# STM32N657 register map
File version: 1.0
CPU: CM55 r0p1, little endian, no MPU, FPU, vendor SysTick, 8 interrupt priority bits
Registers are 32-bit, read-write, reset 0x0 unless marked. A register's access mark holds for its fields unless they carry their own. Offsets are from the block's base; [hi:lo] are bit positions; {n}, {i} and the like mark numbered series; 'fields as' and 'values as' point back to an identical list.

## FMC1 — Flexible memory controller
Base 0x48024000
Same registers: FMC1_S 0x58024000
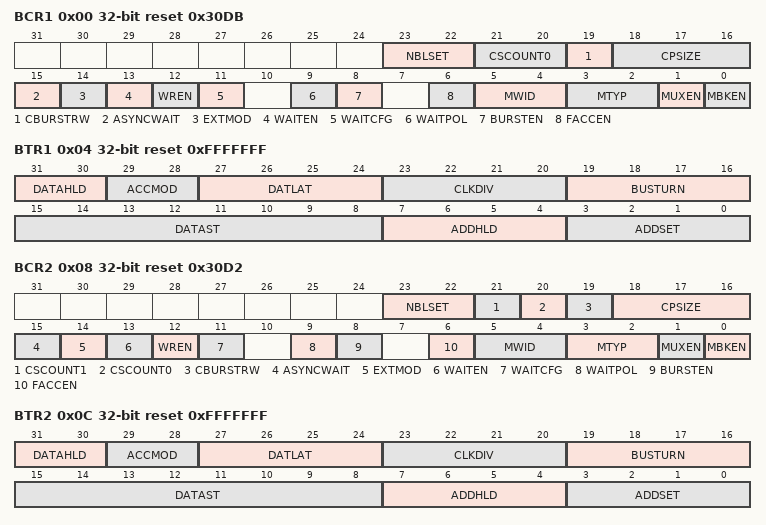
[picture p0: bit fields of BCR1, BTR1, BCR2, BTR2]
0x00 BCR1 reset 0x30DB — SRAM/NOR Flash chip-select control register for memory region 1
  [23:22] NBLSET — Byte lane (NBL) setup
  [21:20] CSCOUNT0 — Chip Select (CS) counter
  [19] CBURSTRW — Write burst enable
  [18:16] CPSIZE — CRAM page size
  [15] ASYNCWAIT — Wait signal during asynchronous transfers
  [14] EXTMOD — Extended mode enable
  [13] WAITEN — Wait enable bit
  [12] WREN — Write enable bit
  [11] WAITCFG — Wait timing configuration
  [9] WAITPOL — Wait signal polarity bit
  [8] BURSTEN — Burst enable bit
  [6] FACCEN — Flash memory access enable
  [5:4] MWID — Memory data bus width
  [3:2] MTYP — Memory type
  [1] MUXEN — Address/data multiplexing enable bit
  [0] MBKEN — Memory region enable bit
0x04 BTR1 reset 0xFFFFFFF — SRAM/NOR Flash chip-select timing registers for memory region 1
  [31:30] DATAHLD — Data Hold phase duration
  [29:28] ACCMOD — Access mode
  [27:24] DATLAT — Data latency for synchronous memory (see note below bit descriptions)
  [23:20] CLKDIV — Clock divide ratio (for FMC_CLK signal)
  [19:16] BUSTURN — Bus turnaround phase duration
  [15:8] DATAST — Data-phase duration
  [7:4] ADDHLD — Address-hold phase duration
  [3:0] ADDSET — Address setup phase duration
0x08 BCR2 reset 0x30D2 — SRAM/NOR Flash chip-select control register for memory region 2
  [23:22] NBLSET — Byte lane (NBL) setup
  [21] CSCOUNT1 — Chip Select (CS) counter
  [20] CSCOUNT0 — Chip Select (CS) counter
  [19] CBURSTRW — Write burst enable
  [18:16] CPSIZE — CRAM page size
  [15] ASYNCWAIT — Wait signal during asynchronous transfers
  [14] EXTMOD — Extended mode enable
  [13] WAITEN — Wait enable bit
  [12] WREN — Write enable bit
  [11] WAITCFG — Wait timing configuration
  [9] WAITPOL — Wait signal polarity bit
  [8] BURSTEN — Burst enable bit
  [6] FACCEN — Flash memory access enable
  [5:4] MWID — Memory data bus width
  [3:2] MTYP — Memory type
  [1] MUXEN — Address/data multiplexing enable bit
  [0] MBKEN — Memory region enable bit
0x0C BTR2 reset 0xFFFFFFF — SRAM/NOR Flash chip-select timing registers for memory region 2
  fields as BTR1
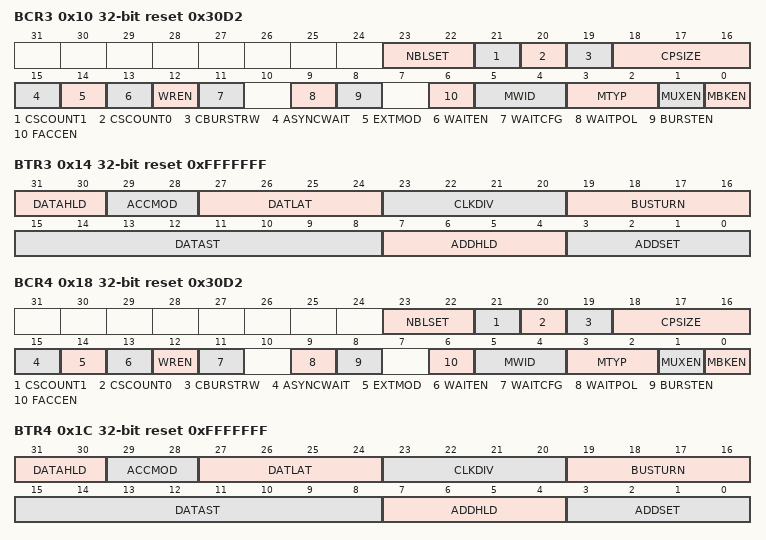
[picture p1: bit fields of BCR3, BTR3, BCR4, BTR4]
0x10 BCR3 reset 0x30D2 — SRAM/NOR Flash chip-select control register for memory region 3
  fields as BCR2
0x14 BTR3 reset 0xFFFFFFF — SRAM/NOR Flash chip-select timing registers for memory region 3
  fields as BTR1
0x18 BCR4 reset 0x30D2 — SRAM/NOR Flash chip-select control register for memory region 4
  fields as BCR2
0x1C BTR4 reset 0xFFFFFFF — SRAM/NOR Flash chip-select timing registers for memory region 4
  fields as BTR1
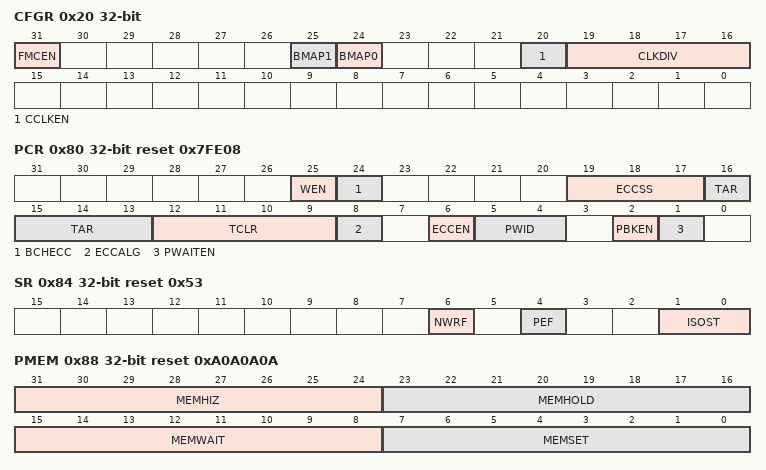
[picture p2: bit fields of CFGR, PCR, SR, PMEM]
0x20 CFGR — FMC common configuration register
  [31] FMCEN — FMC controller enable
  [25] BMAP1 — FMC memory region mapping
  [24] BMAP0 — FMC memory region mapping
  [20] CCLKEN — Continuous clock enable
  [19:16] CLKDIV — Clock divide ratio (for FMC_CLK signal)
0x80 PCR reset 0x7FE08 — NAND Flash programmable control register
  [25] WEN — Write enable
  [24] BCHECC — BCH error correction capability
  [19:17] ECCSS — ECC sector size (used to access spare area)
  [16:13] TAR — ALE to RE delay.
  [12:9] TCLR — CLE to RE delay.
  [8] ECCALG — ECC algorithm
  [6] ECCEN — ECC computation logic enable bit
  [5:4] PWID — Data bus width
  [2] PBKEN — NAND Flash memory region enable bit
  [1] PWAITEN — Wait feature enable bit
0x84 SR ro reset 0x53 — FMC status register
  [6] NWRF — NAND write request flag
  [4] PEF — Pipe Empty Flag
  [1:0] ISOST — FMC isolation state with respect to the AXI interface
0x88 PMEM reset 0xA0A0A0A — FMC common memory space timing register
  [31:24] MEMHIZ — Common memory data bus Hi-Z time
  [23:16] MEMHOLD — Common memory hold time
  [15:8] MEMWAIT — Common memory wait time
  [7:0] MEMSET — Common memory setup time
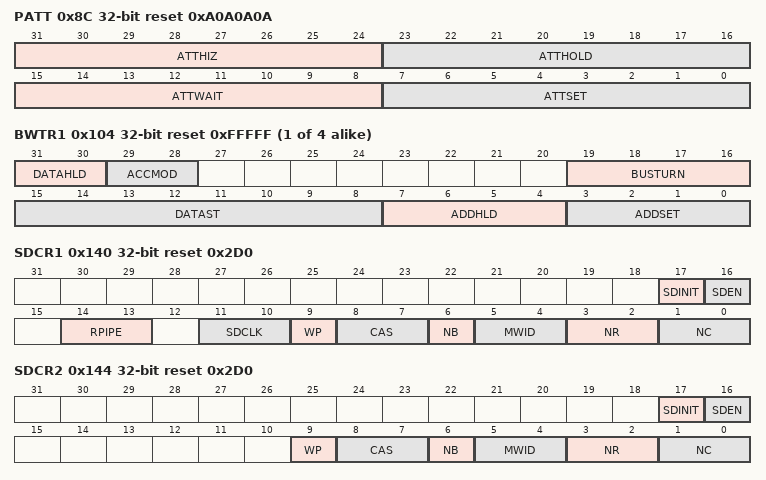
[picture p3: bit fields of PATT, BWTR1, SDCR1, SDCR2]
0x8C PATT reset 0xA0A0A0A — FMC attribute memory space timing registers
  [31:24] ATTHIZ — Attribute memory data bus Hi-Z time
  [23:16] ATTHOLD — Attribute memory hold time
  [15:8] ATTWAIT — Attribute memory wait time
  [7:0] ATTSET — Attribute memory setup time
0x90 HPR ro — FMC Hamming parity result registers
  [31:0] HPR — Hamming parity result
0x94 HECCR ro — FMC Hamming code ECC result register
  [31:0] HECC — ECC result
{0xFC+8i} BWTR{i} reset 0xFFFFF (i=1..4) — SRAM/NOR-Flash write timing registers for memory region {i}
  [31:30] DATAHLD — Data Hold phase duration
  [29:28] ACCMOD — Access mode.
  [19:16] BUSTURN — Bus turnaround phase duration
  [15:8] DATAST — Data-phase duration.
  [7:4] ADDHLD — Address-hold phase duration.
  [3:0] ADDSET — Address setup phase duration.
0x140 SDCR1 reset 0x2D0 — SDRAM control registers for SDRAM device 1
  [17] SDINIT — SDRAM device initialization
  [16] SDEN — SDRAM device enable
  [14:13] RPIPE — Read pipe
  [11:10] SDCLK — SDRAM clock configuration
  [9] WP — Write protection
  [8:7] CAS — CAS Latency
  [6] NB — Number of banks
  [5:4] MWID — Memory data bus width.
  [3:2] NR — Number of row address bits
  [1:0] NC — Number of column address bits
0x144 SDCR2 reset 0x2D0 — SDRAM control registers for SDRAM device 2
  [17] SDINIT — SDRAM device initialization
  [16] SDEN — SDRAM device enable
  [9] WP — Write protection
  [8:7] CAS — CAS Latency
  [6] NB — Number of banks
  [5:4] MWID — Memory data bus width.
  [3:2] NR — Number of row address bits
  [1:0] NC — Number of column address bits
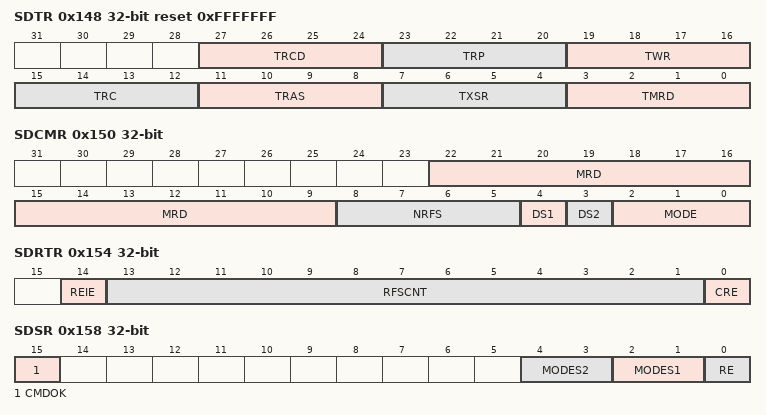
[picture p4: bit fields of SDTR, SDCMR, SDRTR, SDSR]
0x148 SDTR reset 0xFFFFFFF — SDRAM timing register
  [27:24] TRCD — Row to column delay
  [23:20] TRP — Row precharge delay
  [19:16] TWR — Recovery delay
  [15:12] TRC — Row cycle delay
  [11:8] TRAS — Self-refresh time
  [7:4] TXSR — Exit self-refresh delay
  [3:0] TMRD — Load mode register to active
0x150 SDCMR access per field — SDRAM command mode register
  [22:9] MRD rw — Mode register definition
  [8:5] NRFS rw — Number of Refresh commands
  [4] DS1 wo — Command targeting SDRAM device 1
  [3] DS2 wo — Command targeting SDRAM device 2
  [2:0] MODE wo — Command mode
0x154 SDRTR access per field — SDRAM refresh timer register
  [14] REIE rw — RES Interrupt Enable
  [13:1] RFSCNT rw — Refresh Timer Count
  [0] CRE wo — Clear Refresh error flag
0x158 SDSR ro — SDRAM status register
  [15] CMDOK — Previous command status
  [4:3] MODES2 — Status mode for SDRAM device 2
  [2:1] MODES1 — Status Mode for SDRAM device 1
  [0] RE — Refresh error flag
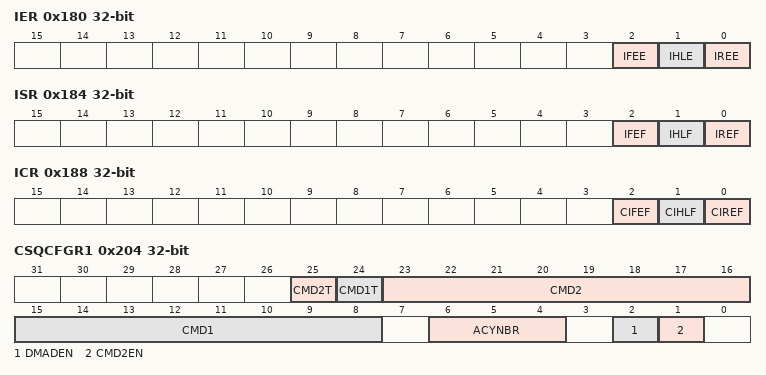
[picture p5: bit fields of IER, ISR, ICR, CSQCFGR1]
0x180 IER — FMC NAND interrupt enable register
  [2] IFEE — Interrupt falling edge detection enable bit
  [1] IHLE — Interrupt high-level detection enable bit
  [0] IREE — Interrupt rising edge detection enable bit
0x184 ISR ro — FMC controller interrupt status register
  [2] IFEF — Interrupt falling edge flag
  [1] IHLF — Interrupt high-level flag
  [0] IREF — Interrupt rising edge flag
0x188 ICR wo — FMC NAND controller interrupt clear register
  [2] CIFEF — Clear Interrupt falling edge flag
  [1] CIHLF — Clear Interrupt high-level flag
  [0] CIREF — Clear Interrupt rising edge flag
0x200 CSQCR wo — FMC NAND command sequencer control register
  [0] CSQSTART — Command Sequencer Enable
0x204 CSQCFGR1 — FMC NAND command sequencer configuration register 1
  [25] CMD2T — Command 2 Sequencer timings
  [24] CMD1T — Command 1 Sequencer timings
  [23:16] CMD2 — Command 2 sequencer
  [15:8] CMD1 — Command 1 sequencer
  [6:4] ACYNBR — Address Cycle number
  [2] DMADEN — Command sequencer DMA request data enable
  [1] CMD2EN — Command cycle 2 Enable
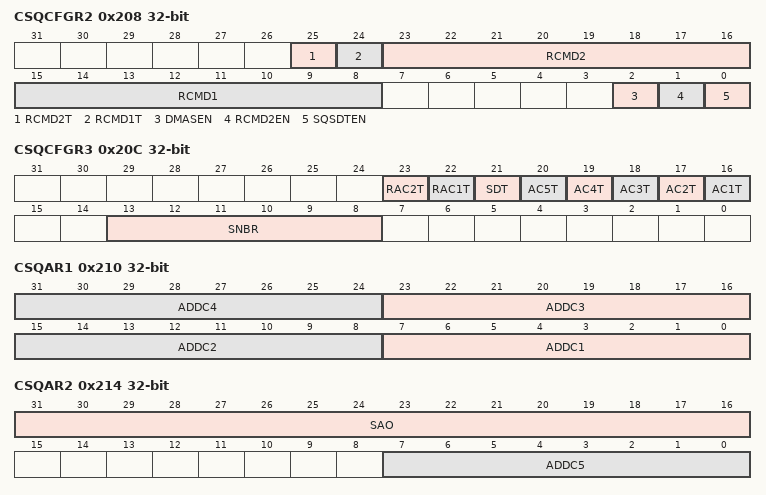
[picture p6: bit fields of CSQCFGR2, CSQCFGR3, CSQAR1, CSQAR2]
0x208 CSQCFGR2 — FMC NAND command sequencer configuration register 2
  [25] RCMD2T — Command 1 sequencer timings
  [24] RCMD1T — Command 1 sequencer timings
  [23:16] RCMD2 — Random Command 2 sequencer
  [15:8] RCMD1 — Random Command 1 sequencer
  [2] DMASEN — Command sequencer DMA request decoding status enable
  [1] RCMD2EN — Random Command 2 sequencer enable
  [0] SQSDTEN — Sequencer spare data transfer enable
0x20C CSQCFGR3 — FMC NAND sequencer configuration register 3
  [23] RAC2T — Random Address cycle 2 sequencer timings
  [22] RAC1T — Random Address cycle 1 sequencer timings
  [21] SDT — Spare data transfer sequencer timings
  [20] AC5T — Address cycle 5 sequencer timings
  [19] AC4T — Address cycle 4sequencer timings
  [18] AC3T — Address cycle 3 sequencer timings
  [17] AC2T — Address cycle 2 sequencer timings
  [16] AC1T — Address cycle 1 sequencer timings
  [13:8] SNBR — Number of sectors to be read/written
0x210 CSQAR1 — FMC NAND command sequencer address register 1
  [8n-1:8n-8] ADDC{n} (n=1..4) — Address Cycle {n}
0x214 CSQAR2 — FMC NAND command sequencer address register 2
  [31:16] SAO — Spare Area Address Offset
  [7:0] ADDC5 — Address Cycle 5
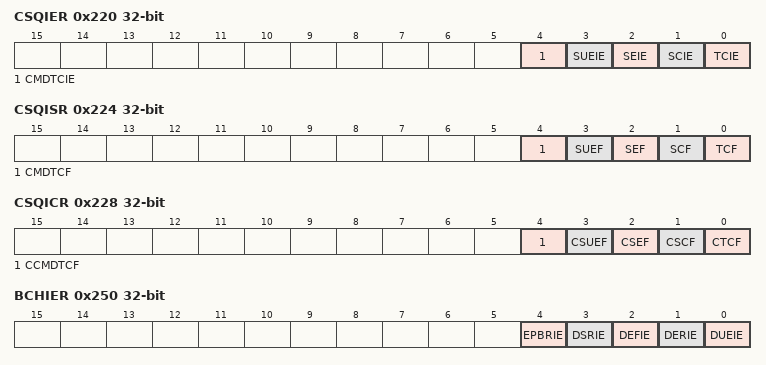
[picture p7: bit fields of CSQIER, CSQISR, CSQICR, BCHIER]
0x220 CSQIER — FMC NAND command sequencer interrupt enable register
  [4] CMDTCIE — Command Transfer Complete interrupt enable
  [3] SUEIE — Sector Uncorrectable Error interrupt enable
  [2] SEIE — Sector Error interrupt enable
  [1] SCIE — Sector Complete interrupt enable
  [0] TCIE — Transfer Complete Interrupt enable
0x224 CSQISR — FMC NAND command sequencer interrupt status register
  [4] CMDTCF — Command Transfer Complete flag
  [3] SUEF — Sector Uncorrectable Error flag
  [2] SEF — Sector Error flag
  [1] SCF — Sector Complete flag
  [0] TCF — Transfer Complete flag
0x228 CSQICR wo — FMC NAND command sequencer interrupt clear register
  [4] CCMDTCF — Clear Command Transfer Complete flag
  [3] CSUEF — Clear Sector uncorrectable Error flag
  [2] CSEF — Clear Sector Error flag
  [1] CSCF — Clear Sector Complete flag
  [0] CTCF — Clear Transfer Complete flag
0x230 CSQEMSR ro — FMC command sequencer error mapping status register
  [15:0] SEM — Sector Error mapping
0x250 BCHIER — FMC BCH interrupt enable register
  [4] EPBRIE — Decoder Parity Bits Ready Interrupt enable
  [3] DSRIE — Decoder Syndrome Ready Interrupt enable
  [2] DEFIE — Decoder Error Found Interrupt enable
  [1] DERIE — Decoder Error Ready Interrupt enable
  [0] DUEIE — Decoder Uncorrectable Errors Interrupt enable
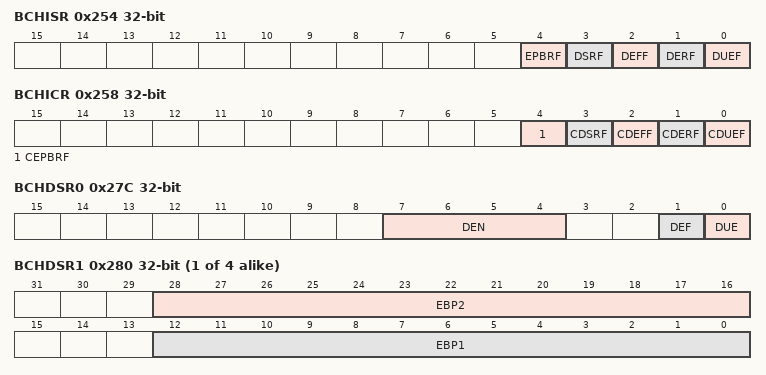
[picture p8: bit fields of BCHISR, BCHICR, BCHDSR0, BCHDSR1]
0x254 BCHISR ro — FMC BCH interrupt and status register
  [4] EPBRF — Encoder Parity Bits Ready flag
  [3] DSRF — Decoder Syndrome Ready flag
  [2] DEFF — Decoder Error Found flag
  [1] DERF — Decoder Error Ready flag
  [0] DUEF — Decoder Uncorrectable Errors flag
0x258 BCHICR wo — FMC BCH interrupt clear register
  [4] CEPBRF — Clear Encoder Parity Bits Ready flag
  [3] CDSRF — Clear Decoder Syndrome Ready flag
  [2] CDEFF — Clear Decoder Error Found flag
  [1] CDERF — Clear Decoder Error ready flag
  [0] CDUEF — Clear Decoder Uncorrectable Error flag
{0x25C+4i} BCHPBR{i} ro (i=1..3) — FMC BCH parity bits register {i}
  [31:0] BCHPB — BCH parity bits
0x26C BCHPBR4 ro — FMC BCH parity bits register 4
  [7:0] BCHPB — BCH parity bits
0x27C BCHDSR0 ro — FMC BCH decoder status register 0
  [7:4] DEN — Decoder error number
  [1] DEF — Decoder error found
  [0] DUE — Decoder uncorrectable error
{0x27C+4i} BCHDSR{i} ro (i=1..4) — FMC BCH decoder status register for memory region {i}
  [28:16] EBP{2i} — Error bit position for error number {2i}
  [12:0] EBP{2i-1} — Error bit position for error number {2i-1}
